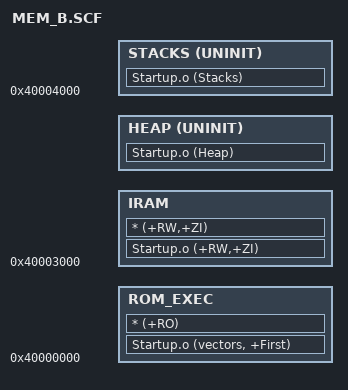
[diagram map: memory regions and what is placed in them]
;/********************************************************************************************************
;**--------------文件信息--------------------------------------------------------------------------------
;**文   件   名: mem_b.scf
;**描        述: 分散加载文件，决定各个代码段和数据段的存储位置（用于调试）
;**              每个工程应当有独立的这个文件的拷贝，并进行相应的修改   
;********************************************************************************************************/

ROM_LOAD 0x40000000
{
    ROM_EXEC 0x40000000
    {
        Startup.o (vectors, +First)
        * (+RO)
    }

    IRAM 0x40003000
    {
        Startup.o (+RW,+ZI)
        * (+RW,+ZI)
    }
   
    HEAP +0 UNINIT
    {
        Startup.o (Heap)
    }

    STACKS 0x40004000 UNINIT
    {
        Startup.o (Stacks)
    }

}

